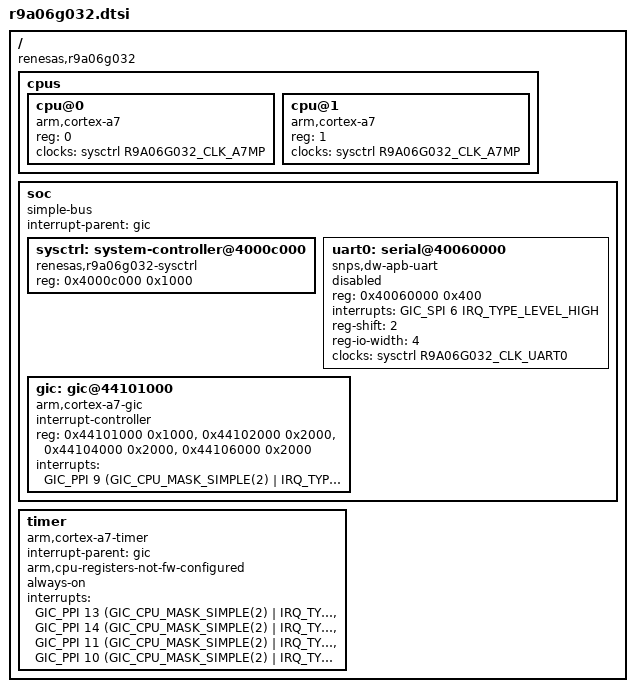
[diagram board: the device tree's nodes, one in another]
// SPDX-License-Identifier: GPL-2.0
/*
 * Base Device Tree Source for the Renesas RZ/N1D (R9A06G032)
 *
 * Copyright (C) 2018 Renesas Electronics Europe Limited
 *
 */

#include <dt-bindings/interrupt-controller/arm-gic.h>
#include <dt-bindings/clock/r9a06g032-sysctrl.h>

/ {
	compatible = "renesas,r9a06g032";
	#address-cells = <1>;
	#size-cells = <1>;

	cpus {
		#address-cells = <1>;
		#size-cells = <0>;

		cpu@0 {
			device_type = "cpu";
			compatible = "arm,cortex-a7";
			reg = <0>;
			clocks = <&sysctrl R9A06G032_CLK_A7MP>;
		};

		cpu@1 {
			device_type = "cpu";
			compatible = "arm,cortex-a7";
			reg = <1>;
			clocks = <&sysctrl R9A06G032_CLK_A7MP>;
		};
	};

	soc {
		compatible = "simple-bus";
		#address-cells = <1>;
		#size-cells = <1>;
		interrupt-parent = <&gic>;
		ranges;

		sysctrl: system-controller@4000c000 {
			compatible = "renesas,r9a06g032-sysctrl";
			reg = <0x4000c000 0x1000>;
			status = "okay";
			#clock-cells = <1>;
		};

		uart0: serial@40060000 {
			compatible = "snps,dw-apb-uart";
			reg = <0x40060000 0x400>;
			interrupts = <GIC_SPI 6 IRQ_TYPE_LEVEL_HIGH>;
			reg-shift = <2>;
			reg-io-width = <4>;
			clocks = <&sysctrl R9A06G032_CLK_UART0>;
			clock-names = "baudclk";
			status = "disabled";
		};

		gic: gic@44101000 {
			compatible = "arm,cortex-a7-gic", "arm,gic-400";
			interrupt-controller;
			#interrupt-cells = <3>;
			reg = <0x44101000 0x1000>, /* Distributer */
			      <0x44102000 0x2000>, /* CPU interface */
			      <0x44104000 0x2000>, /* Virt interface control */
			      <0x44106000 0x2000>; /* Virt CPU interface */
			interrupts =
				<GIC_PPI 9 (GIC_CPU_MASK_SIMPLE(2) | IRQ_TYPE_LEVEL_HIGH)>;
		};
	};

	timer {
		compatible = "arm,cortex-a7-timer",
			     "arm,armv7-timer";
		interrupt-parent = <&gic>;
		arm,cpu-registers-not-fw-configured;
		always-on;
		interrupts =
			<GIC_PPI 13 (GIC_CPU_MASK_SIMPLE(2) | IRQ_TYPE_LEVEL_LOW)>,
			<GIC_PPI 14 (GIC_CPU_MASK_SIMPLE(2) | IRQ_TYPE_LEVEL_LOW)>,
			<GIC_PPI 11 (GIC_CPU_MASK_SIMPLE(2) | IRQ_TYPE_LEVEL_LOW)>,
			<GIC_PPI 10 (GIC_CPU_MASK_SIMPLE(2) | IRQ_TYPE_LEVEL_LOW)>;
	};
};
